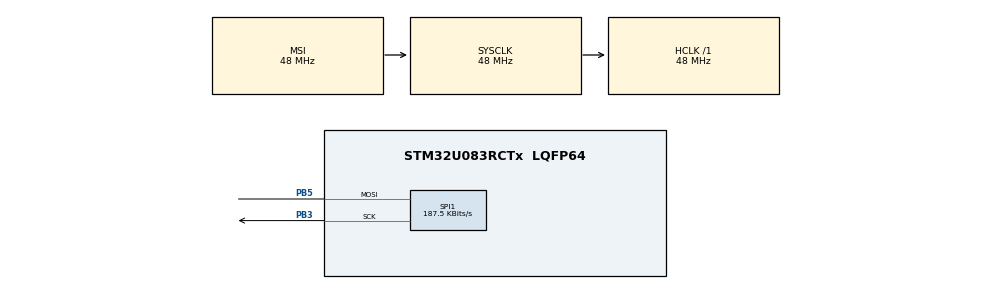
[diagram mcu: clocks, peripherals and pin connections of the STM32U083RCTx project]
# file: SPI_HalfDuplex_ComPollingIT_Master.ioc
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Mcu.Family=STM32U0
Mcu.Name=STM32U083RCTx
Mcu.Package=LQFP64
NVIC.PriorityGroup=NVIC_PRIORITYGROUP_2
PB3.GPIO_PuPd=GPIO_PULLDOWN
PB3.GPIO_Speed=GPIO_SPEED_FREQ_VERY_HIGH
PB3.Mode=Simplex_Bidirectional_Master
PB3.Signal=SPI1_SCK
PB5.GPIO_Mode=GPIO_MODE_AF_PP
PB5.GPIO_PuPd=GPIO_PULLDOWN
PB5.GPIO_Speed=GPIO_SPEED_FREQ_VERY_HIGH
PB5.Mode=Simplex_Bidirectional_Master
PB5.Signal=SPI1_MOSI
ProjectManager.HeapSize=0x200
ProjectManager.StackSize=0x400
ProjectManager.TargetToolchain=EWARM V9.20
RCC.ADCFreq_Value=48000000
RCC.AHBFreq_Value=48000000
RCC.CortexFreq_Value=48000000
RCC.HCLKFreq_Value=48000000
RCC.HSE_VALUE=4000000
RCC.HSI48_VALUE=48000000
RCC.HSI_VALUE=16000000
RCC.LSE_VALUE=32768
RCC.MSIClockRangeVal=RCC_MSIRANGE_11
RCC.MSI_VALUE=48000000
RCC.PLLM=RCC_PLLM_DIV8
RCC.PLLN=8
RCC.PLLSourceVirtual=RCC_PLLSOURCE_MSI
RCC.SYSCLKFreq_VALUE=48000000
RCC.SYSCLKSource=RCC_SYSCLKSOURCE_MSI
RCC.USBFreq_Value=48000000
RCC.VCOOutputFreq_Value=48000000
SPI1.BaudRatePrescaler=SPI_BAUDRATEPRESCALER_256
SPI1.CalculateBaudRate=187.5 KBits/s
SPI1.DataSize=SPI_DATASIZE_8BIT
SPI1.Direction=SPI_DIRECTION_1LINE
SPI1.Mode=SPI_MODE_MASTER
SPI1.NSSPMode=SPI_NSS_PULSE_DISABLE
SPI1.VirtualType=VM_MASTER
VP_PWR_VS_SECSignals.Mode=Security/Privilege
board=custom

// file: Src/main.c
/* USER CODE BEGIN Header */
/**
  ******************************************************************************
  * @file    SPI/SPI_FullDuplex_ComIT_Master/Src/main.c
  * @author  MCD Application Team
  * @brief   This sample code shows how to use STM32U0xx SPI HAL API to transmit
  *          and receive a data buffer with a communication process based on
  *          Interrupt transfer.
  *          The communication is done using 2 Boards.
  ******************************************************************************
  * @attention
  *
  * Copyright (c) 2023 STMicroelectronics.
  * All rights reserved.
  *
  * This software is licensed under terms that can be found in the LICENSE file
  * in the root directory of this software component.
  * If no LICENSE file comes with this software, it is provided AS-IS.
  *
  ******************************************************************************
  */
/* USER CODE END Header */
#include "main.h"

/* USER CODE BEGIN PD */
enum {
	TRANSFER_WAIT,
	TRANSFER_COMPLETE,
	TRANSFER_ERROR
};
/* USER CODE END PD */

SPI_HandleTypeDef hspi1;

/* USER CODE BEGIN PV */
/* Buffer used for transmission */
uint8_t aTxBuffer[] = "**** SPI - Two Boards communication based on Polling (LL driver) for Master Board and Interrupt (HAL Driver) for Slave Board ****";
__IO uint8_t ubNbDataToTransmit  = BUFFERSIZE;
__IO uint8_t ubNbDataTransmitted = 0;

/* Buffer used for reception */
uint8_t aRxBuffer[sizeof(aTxBuffer)];

/* transfer state */
__IO uint32_t wTransferState = TRANSFER_WAIT;
/* USER CODE END PV */

void SystemClock_Config(void);
static void MX_GPIO_Init(void);
static void MX_SPI1_Init(void);

int main(void)
{
  /* USER CODE BEGIN 1 */

  /* STM32U0xx HAL library initialization:
       - Configure the Flash prefetch
       - Systick timer is configured by default as source of time base, but user
         can eventually implement his proper time base source (a general purpose
         timer for example or other time source), keeping in mind that Time base
         duration should be kept 1ms since PPP_TIMEOUT_VALUEs are defined and
         handled in milliseconds basis.
       - Low Level Initialization
     */
  /* USER CODE END 1 */

  /* MCU Configuration--------------------------------------------------------*/

  /* Reset of all peripherals, Initializes the Flash interface and the Systick. */
  HAL_Init();

  /* Configure the system clock */
  SystemClock_Config();

  /* Initialize all configured peripherals */
  MX_GPIO_Init();
  MX_SPI1_Init();
  /* USER CODE BEGIN 2 */

  /* Configure LED4 */
  BSP_LED_Init(LED4);

  /* Configure User push-button */
  BSP_PB_Init(BUTTON_USER, BUTTON_MODE_GPIO);

  /* Wait for User push-button press before starting the Communication */
  while (BSP_PB_GetState(BUTTON_USER) != GPIO_PIN_RESET)
  {
    BSP_LED_Toggle(LED4);
    HAL_Delay(100);
  }
  BSP_LED_Off(LED4);

  /*##-1- Start the Half Duplex Communication process ########################*/
  /* Half Duplex Direction (Tx) not Done by HAL_Init. */
  LL_SPI_SetTransferDirection(hspi1.Instance, LL_SPI_HALF_DUPLEX_TX);

  /* Enable SPI before start transmission */
  LL_SPI_Enable(hspi1.Instance);

  while(ubNbDataToTransmit > 0)
  {
    /* Check TXE flag to transmit data */
    if(LL_SPI_IsActiveFlag_TXE(hspi1.Instance))
    {
      /* Transmit 8bit Data */
      LL_SPI_TransmitData8(hspi1.Instance, aTxBuffer[ubNbDataTransmitted++]);
      ubNbDataToTransmit--;
    }
  }

  /* Wait End Of Transmission: TXE set and Tx Fifo empty */

  while((LL_SPI_IsActiveFlag_TXE(hspi1.Instance) != 1));
  while(LL_SPI_GetTxFIFOLevel(hspi1.Instance) != LL_SPI_TX_FIFO_EMPTY);

  /* Disable SPI after End of Transmission */
  LL_SPI_Disable(hspi1.Instance);

  /* USER CODE END 2 */

  /* Infinite loop */
  while (1)
  {

  }
}

void SystemClock_Config(void)
{
  RCC_OscInitTypeDef RCC_OscInitStruct = {0};
  RCC_ClkInitTypeDef RCC_ClkInitStruct = {0};

  /** Configure the main internal regulator output voltage
  */
  HAL_PWREx_ControlVoltageScaling(PWR_REGULATOR_VOLTAGE_SCALE1);

  /** Initializes the RCC Oscillators according to the specified parameters
  * in the RCC_OscInitTypeDef structure.
  */
  RCC_OscInitStruct.OscillatorType = RCC_OSCILLATORTYPE_MSI;
  RCC_OscInitStruct.MSIState = RCC_MSI_ON;
  RCC_OscInitStruct.MSICalibrationValue = RCC_MSICALIBRATION_DEFAULT;
  RCC_OscInitStruct.MSIClockRange = RCC_MSIRANGE_11;
  RCC_OscInitStruct.PLL.PLLState = RCC_PLL_NONE;
  if (HAL_RCC_OscConfig(&RCC_OscInitStruct) != HAL_OK)
  {
    Error_Handler();
  }

  /** Initializes the CPU, AHB and APB buses clocks
  */
  RCC_ClkInitStruct.ClockType = RCC_CLOCKTYPE_HCLK|RCC_CLOCKTYPE_SYSCLK
                              |RCC_CLOCKTYPE_PCLK1;
  RCC_ClkInitStruct.SYSCLKSource = RCC_SYSCLKSOURCE_MSI;
  RCC_ClkInitStruct.AHBCLKDivider = RCC_SYSCLK_DIV1;
  RCC_ClkInitStruct.APB1CLKDivider = RCC_HCLK_DIV1;

  if (HAL_RCC_ClockConfig(&RCC_ClkInitStruct, FLASH_LATENCY_1) != HAL_OK)
  {
    Error_Handler();
  }
}

static void MX_SPI1_Init(void)
{

  /* SPI1 parameter configuration*/
  hspi1.Instance = SPI1;
  hspi1.Init.Mode = SPI_MODE_MASTER;
  hspi1.Init.Direction = SPI_DIRECTION_1LINE;
  hspi1.Init.DataSize = SPI_DATASIZE_8BIT;
  hspi1.Init.CLKPolarity = SPI_POLARITY_LOW;
  hspi1.Init.CLKPhase = SPI_PHASE_1EDGE;
  hspi1.Init.NSS = SPI_NSS_SOFT;
  hspi1.Init.BaudRatePrescaler = SPI_BAUDRATEPRESCALER_256;
  hspi1.Init.FirstBit = SPI_FIRSTBIT_MSB;
  hspi1.Init.TIMode = SPI_TIMODE_DISABLE;
  hspi1.Init.CRCCalculation = SPI_CRCCALCULATION_DISABLE;
  hspi1.Init.CRCPolynomial = 7;
  hspi1.Init.CRCLength = SPI_CRC_LENGTH_DATASIZE;
  hspi1.Init.NSSPMode = SPI_NSS_PULSE_DISABLE;
  if (HAL_SPI_Init(&hspi1) != HAL_OK)
  {
    Error_Handler();
  }

}

static void MX_GPIO_Init(void)
{

  /* GPIO Ports Clock Enable */
  __HAL_RCC_GPIOB_CLK_ENABLE();

}

void Error_Handler(void)
{
  /* USER CODE BEGIN Error_Handler_Debug */
  /* User can add his own implementation to report the HAL error return state */
  while(1)
  {
    /* Toggle LED4 for error */
    BSP_LED_Toggle(LED4);
    HAL_Delay(1000);
  }
  /* USER CODE END Error_Handler_Debug */
}
